# A31L12x register map
Vendor: VENDOR ABOV Semiconductor Co., Ltd.; Series: A31L12x; File version: 1.0
CPU: CM0+ r0p1, little endian, no MPU, no FPU, VTOR, 2 interrupt priority bits
Registers are 32-bit, read-write, reset 0x0 unless marked. A register's access mark holds for its fields unless they carry their own. Offsets are from the block's base; [hi:lo] are bit positions; {n}, {i} and the like mark numbered series; 'fields as' and 'values as' point back to an identical list.

## SCn — SC n (SCI + UART)
Base 0x56000000
Same registers: SC0 0x40005300, SC1 0x40005380
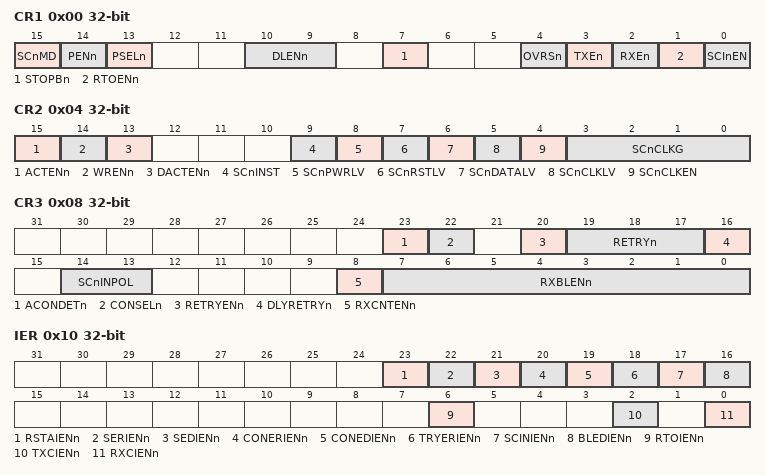
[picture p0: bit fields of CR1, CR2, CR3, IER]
0x00 CR1 — SCn Control Register 1
  [15] SCnMD — Smartcard Interface Mode Selection
    0=SCI (Smartcard interface mode (SCnPWR/RST/CLK/DATA/IN)); 1=UART (UART mode (SCnRXD/TXD))
  [14] PENn — Parity Enable
    0=Disable parity bit generation and detection; 1=Enable parity bit generation and detection
  [13] PSELn — Parity Selection
    0=Odd (Odd parity (Odd number of logic '1')); 1=Even parity (Even number of logic '1')
  [10:9] DLENn — Data Length Selection
    0=5bit. Start,D0,D1,D2,D3,D4,(Parity),Stop1,(Stop2); 1=6bit. Start,D0,D1,D2,D3,D4,D5,(Parity),Stop1,(Stop2); 2=7bit. Start,D0,D1,D2,D3,D4,D5,D6,(Parity),Stop1,(Stop2); 3=8bit. Start,D0,D1,D2,D3,D4,D5,D6,D7,(Parity),Stop1,(Stop2)
  [7] STOPBn — Stop bit length
    0=1bit (1 Stop bit); 1=2bit (2 Stop bits)
  [4] OVRSn — Oversampling Selection
    0=16 oversampling; 1=8 oversampling
  [3] TXEn — Enable the transmitter unit.
    0=Disable (Transmitter is disabled.); 1=Enable (Transmitter is enabled.)
  [2] RXEn — Enable the receiver unit.
    0=Disable (Receiver is disabled.); 1=Enable (Receiver is enabled.)
  [1] RTOENn — Receive Time Out Function Enable
    0=Disable receive time out function; 1=Enable receive time out function
  [0] SCInEN — Smartcard Interface Block Enable
    0=Disable SCn block; 1=Enable SCn block
0x04 CR2 — SCn Control Register 2 (only used for Smardcard Interface Mode)
  [15] ACTENn — Auto Activation Enable
    0=NoEffect; 1=Enable activation and cold reset. (This bit is automatically cleared after operation)
  [14] WRENn — Auto Warm Reset Enable
    0=NoEffect; 1=Enable warm reset. (This bit is automatically cleared after operation)
  [13] DACTENn — Auto Deactivation Enable
    0=NoEffect; 1=Enable deactivation. (This bit is automatically cleared after operation)
  [9] SCnINST ro — SCnIN Pin Status
    0=LowLevel (SCnIN pin state at low level); 1=HighLevel (SCnIN pin state at high level)
  [8] SCnPWRLV — SCnPWR Pin Level Setting
    0=LowLevel (SCnPWR pin to low level); 1=HighLevel (SCnPWR pin to high level)
  [7] SCnRSTLV — SCnRST Pin Level Setting
    0=LowLevel (SCnRST pin to low level); 1=HighLevel (SCnRST pin to high level)
  [6] SCnDATALV — SCnDATA Pin Level Setting
    0=LowLevel (SCnDATA pin to low level); 1=HighLevel (The SCnDATA pin is high level with an external pull-up resistor and reception mode.)
  [5] SCnCLKLV — SCnCLK Pin Level Setting
    0=LowLevel (SCnCLK pin to low level on clock generation disable); 1=HighLevel (SCnCLK pin to high level on clock generation disable)
  [4] SCnCLKEN — Smartcard Clock Generation Enable
    0=Disable smartcard clock generation; 1=Enable smartcard clock generation
  [3:0] SCnCLKG — This bit-field is used to generate smartcard clock
    0=PCLK1 (Smartcard clock (fsc): PCLK/1 with 1/2 duty); 1=PCLK2 (Smartcard clock (fsc): PCLK/(value x 2) with 1/2 duty); 2=PCLK4 (Smartcard clock (fsc): PCLK/(value x 2) with 1/2 duty); 3=PCLK6 (Smartcard clock (fsc): PCLK/(value x 2) with 1/2 duty); 4=PCLK8 (Smartcard clock (fsc): PCLK/(value x 2) with 1/2 duty); 5=PCLK10 (Smartcard clock (fsc): PCLK/(value x 2) with 1/2 duty); 6=PCLK12 (Smartcard clock (fsc): PCLK/(value x 2) with 1/2 duty); 7=PCLK14 (Smartcard clock (fsc): PCLK/(value x 2) with 1/2 duty); 8=PCLK16 (Smartcard clock (fsc): PCLK/(value x 2) with 1/2 duty); 9=PCLK18 (Smartcard clock (fsc): PCLK/(value x 2) with 1/2 duty); 10=PCLK20 (Smartcard clock (fsc): PCLK/(value x 2) with 1/2 duty); 11=PCLK22 (Smartcard clock (fsc): PCLK/(value x 2) with 1/2 duty); 12=PCLK24 (Smartcard clock (fsc): PCLK/(value x 2) with 1/2 duty); 13=PCLK26 (Smartcard clock (fsc): PCLK/(value x 2) with 1/2 duty); 14=PCLK28 (Smartcard clock (fsc): PCLK/(value x 2) with 1/2 duty); 15=PCLK30 (Smartcard clock (fsc): PCLK/(value x 2) with 1/2 duty)
0x08 CR3 — SCn Control Register 3 (only used for Smardcard Interface Mode)
  [23] ACONDETn — Auto Convention Detection
    0=NoEffect; 1=Enable (Auto convention detection (This bit is automatically cleared after operation))
  [22] CONSELn — Convention Selection
    0=Direct convention (lsb first shift out, 0: Low level, 1: High level); 1=Inverse convention (msb first shift out, 0: High level, 1: low level)
  [20] RETRYENn — Tx/Rx Error Signal Generation/Detection Retry Enable
    0=Disable error signal generation/detection and retry Rx/Tx; 1=Enable error signal generation/detection and retry Rx/Tx
  [19:17] RETRYn — The number of retry. RETRYn[2:0]+1
  [16] DLYRETRYn — Delay Time Before Retry Selection
    0=2D5ETU (2.5 etu delay before re-transmit byte); 1=2D5ETU_EGT (2.5 etu + 'extra guard time' delay before re-transmit byte)
  [14:13] SCnINPOL — SCnIN Pin Input Polarity Selection
    0=FallingEdge (Smartcard Insert/Removal on falling edge); 1=RisingEdge (Smartcard Insert/Removal on rising edge); 2=BothEdge (Smartcard Insert/Removal on both of falling and rising edge)
  [8] RXCNTENn — Received byte Count Enable
    0=NoEffect; 1=Enable (Received block length counts every Rx (This bit is automatically cleared after the BLEDIFGn bit is set))
  [7:0] RXBLENn — Received Block Length
0x10 IER — SCn Interrupt Enable Register
  [23] RSTAIENn — Reset Assertion Interrupt Enable
    0=Disable reset assertion interrupt; 1=Enable reset assertion interrupt
  [22] SERIENn — Sequence Error Interrupt Enable
    0=Disable sequence error interrupt; 1=Enable sequence error interrupt
  [21] SEDIENn — Sequence End Interrupt Enable
    0=Disable sequence end interrupt; 1=Enable sequence end interrupt
  [20] CONERIENn — Convention Detection Error Interrupt Enable
    0=Disable convention detection error interrupt; 1=Enable convention detection error interrupt
  [19] CONEDIENn — Convention Detection End Interrupt Enable
    0=Disable convention detection end interrupt; 1=Enable convention detection end interrupt
  [18] TRYERIENn — Transmit Retry Error Interrupt Enable
    0=Disable transmit retry error interrupt; 1=Enable transmit retry error interrupt
  [17] SCINIENn — SCnIN Pin Valid Edge Interrupt Enable
    0=Disable SCnIN pin valid edge interrupt; 1=Enable SCnIN pin valid edge interrupt
  [16] BLEDIENn — Block Length Count End Interrupt Enable
    0=Disable block length count end interrupt; 1=Enable block length count end interrupt
  [6] RTOIENn — Receive Time Out Interrupt Enable
    0=Disable receive time out interrupt; 1=Enable receive time out interrupt
  [2] TXCIENn — Transmit Complete Interrupt Enable
    0=Disable transmit complete interrupt; 1=Enable transmit complete interrupt
  [0] RXCIENn — Receive Data Register Not Empty Interrupt Enable
    0=Disable receive data not empty interrupt; 1=Enable receive data not empty interrupt
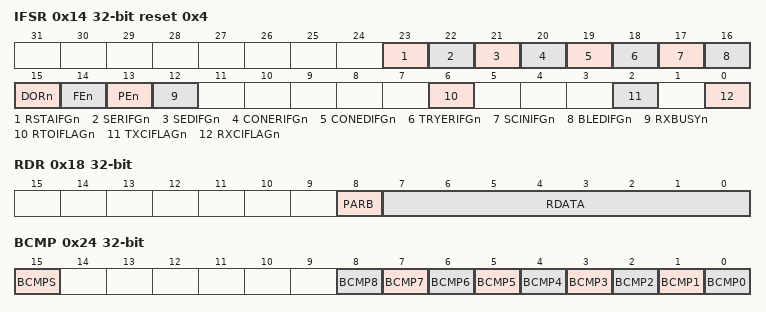
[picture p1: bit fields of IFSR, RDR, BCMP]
0x14 IFSR reset 0x4 — SCn Interrupt Flag and Status Register
  [23] RSTAIFGn — Reset Assertion Interrupt Flag
    0=No request occurred; 1=Request occurred, This bit is cleared to '0' when write '1'
  [22] SERIFGn — Sequence Error Interrupt Flag
    values as RSTAIFGn
  [21] SEDIFGn — Sequence End Interrupt Flag
    values as RSTAIFGn
  [20] CONERIFGn — Convention Detection Error Interrupt Flag
    values as RSTAIFGn
  [19] CONEDIFGn — Convention Detection End Interrupt Flag
    values as RSTAIFGn
  [18] TRYERIFGn — Transmit Retry Error Interrupt Flag
    values as RSTAIFGn
  [17] SCINIFGn — SCnIN Pin Valid Edge Interrupt Flag
    values as RSTAIFGn
  [16] BLEDIFGn — Block Length Count End Interrupt Flag
    values as RSTAIFGn
  [15] DORn — Data Overrun
  [14] FEn — Frame Error
  [13] PEn — Parity Error
  [12] RXBUSYn ro — RXD Line Busy
  [6] RTOIFLAGn — Receive Time Out Interrupt Flag
    values as RSTAIFGn
  [2] TXCIFLAGn — Transmit Complete Interrupt Flag
    0=No request occurred; 1=Request (The data in the transmit shift register are shifted out completely. This bit is cleared to '0' when write '1'.)
  [0] RXCIFLAGn — Receive Data Register Not Empty Interrupt Flag
    0=No request occurred; 1=Request (There is data in the receive data register. This bit is cleared to '0' when write '1'.)
0x18 RDR ro — SCn Receive Data Register
  [8] PARB — Receive Parity
  [7:0] RDATA — Receive Data
0x1C TDR — SCn Transmit Data Register
  [7:0] TDATA — Transmit Data
0x20 BDR reset 0xFFFF — SCn Baud Rate Data Register
  [15:0] BDATA — These bits are used to generate baud rate
0x24 BCMP — SCn Baud Rate Compensation Register
  [15] BCMPS — Baud Rate Compensation Sign
  [n] BCMP{n} (n=0..8) — Baud Rate Compensation {n}
0x28 RTODR reset 0xFFFF — SCn Receive Time Out Data Register
  [23:0] RTOD — SCn Receive Time Out Data
0x2C EGTR — SCn Tx Extra Guard Time Register
  [7:0] EGT — SCn Tx Extra Guard Time
0x30 T3DR — SCn T3 Duration Data Register
  [15:0] T3D — T3 Duration Data bits. T3D[15:0] + 1
0x34 T4DR — SCn T4 Duration Data Register
  [15:0] T4D — T4 Duration Data bits. T4D[15:0] + 1
